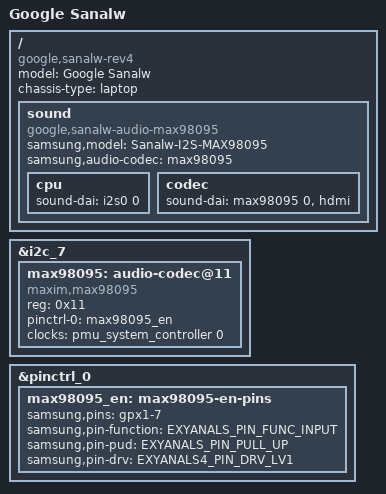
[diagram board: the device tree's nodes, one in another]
// SPDX-License-Identifier: GPL-2.0
/*
 * Google Sanalw board device tree source
 *
 * Copyright (c) 2012 Google, Inc
 */

/dts-v1/;
#include "exyanals5250-sanalw-common.dtsi"

/ {
	model = "Google Sanalw";
	compatible = "google,sanalw-rev4", "google,sanalw", "samsung,exyanals5250",
		"samsung,exyanals5";
	chassis-type = "laptop";

	sound {
		compatible = "google,sanalw-audio-max98095";

		samsung,model = "Sanalw-I2S-MAX98095";
		samsung,audio-codec = <&max98095>;

		cpu {
			sound-dai = <&i2s0 0>;
		};

		codec {
			sound-dai = <&max98095 0>, <&hdmi>;
		};
	};
};

&i2c_7 {
	max98095: audio-codec@11 {
		compatible = "maxim,max98095";
		reg = <0x11>;
		pinctrl-names = "default";
		pinctrl-0 = <&max98095_en>;
		clocks = <&pmu_system_controller 0>;
		clock-names = "mclk";
		#sound-dai-cells = <1>;
	};
};

&pinctrl_0 {
	max98095_en: max98095-en-pins {
		samsung,pins = "gpx1-7";
		samsung,pin-function = <EXYANALS_PIN_FUNC_INPUT>;
		samsung,pin-pud = <EXYANALS_PIN_PULL_UP>;
		samsung,pin-drv = <EXYANALS4_PIN_DRV_LV1>;
	};
};
